# S32R372 register map
Vendor: Freescale Semiconductor, Inc.; Series: Qorivva; File version: 1.6
Registers are 32-bit, read-write, reset 0x0 unless marked. A register's access mark holds for its fields unless they carry their own. Offsets are from the block's base; [hi:lo] are bit positions; {n}, {i} and the like mark numbered series.

## CRC_1 — CRC
Base 0xFBF64000; register names take the prefix CRC_1_
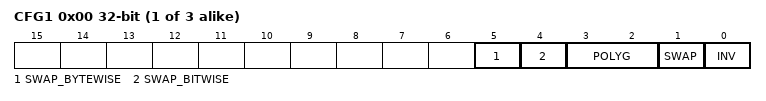
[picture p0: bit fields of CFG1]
0x00 CFG{i} (i=1..3; step 0x10) — Configuration Register
  [5] SWAP_BYTEWISE — Swap CRC_INP byte-wise
    0=Do not swap; 1=Perform byte-wise swap on CRC_INP input data internally for CRC-32 polynomial calculations
  [4] SWAP_BITWISE — Swap CRC_INP bit-wise
    0=Do not swap; 1=Perform bit-wise swap on CRC_INP input data internally for CRC-8 and CRC-16 polynomial calculations
  [3:2] POLYG — Polynomial selection
    0=CRC-CCITT polynomial; 1=CRC-32 polynomial; 2=CRC-8 polynomial; 3=CRC-8-H2F Autosar polynomial
  [1] SWAP — Swap selection
    0=No swap selection applied on the CRC_OUTP content; 1=Swap selection (MSB to LSB, LSB to MSB) applied on the CRC_OUTP content; in case of CRC-CCITT polynomial, the swap operation is applied on the 16 least-significant bits
  [0] INV — Inversion selection
    0=No inversion selection applied on the CRC_OUTP content; 1=Inversion selection (bit x bit) applied on the CRC_OUTP content
0x04 INP{i} (i=1..3; step 0x10) — Input Register
  [31:0] INP — Input data for the CRC computation
0x08 CSTAT{i} (i=1..3; step 0x10) reset 0xFFFFFFFF — Current Status Register
  [31:0] CSTAT — CRC signature status
0x0C OUTP{i} (i=1..3; step 0x10) ro reset 0xFFFFFFFF — Output Register
  [31:0] OUTP — Final CRC signature

## CRC_0 — CRC
Base 0xFFF64000; register names take the prefix CRC_0_
Registers as CRC_1.

## DMAMUX_1 — DMA channel multiplexor
Base 0xFBF6C000; register names take the prefix DMAMUX_1_
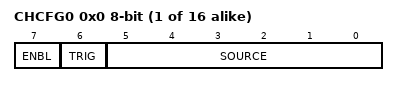
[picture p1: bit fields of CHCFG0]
{0x0+i} CHCFG{i} (i=0..15) 8-bit — Channel Configuration register
  [7] ENBL — DMA Channel Enable
    0=DMA channel is disabled. This mode is primarily used during configuration of the DMAMux. The DMA has separate channel enables/disables, which should be used to disable or reconfigure a DMA channel.; 1=DMA channel is enabled
  [6] TRIG — DMA Channel Trigger Enable
    0=Triggering is disabled. If triggering is disabled and ENBL is set, the DMA Channel will simply route the specified source to the DMA channel. (Normal mode); 1=Triggering is enabled. If triggering is enabled and ENBL is set, the DMAMUX is in Periodic Trigger mode.
  [5:0] SOURCE — DMA Channel Source (Slot)

## DMAMUX_0 — DMA channel multiplexor
Base 0xFFF6C000; register names take the prefix DMAMUX_0_
Registers as DMAMUX_1.

## CMU_0 — CMU
Base 0xFBFB0200; register names take the prefix CMU_0_
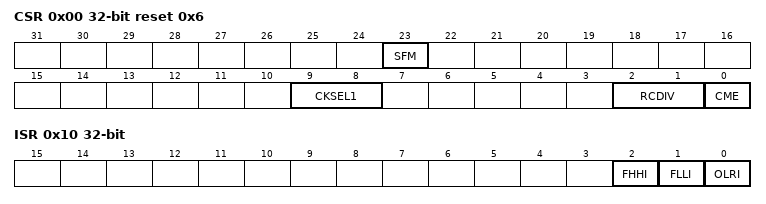
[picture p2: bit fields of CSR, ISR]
0x00 CSR reset 0x6 — CMU Control Status Register
  [23] SFM — Start frequency measure.
    0=Frequency measurement is completed or not yet started; 1=Frequency measurement is not completed
  [9:8] CKSEL1 — Frequency measure clock selection bit.
    0=CLKMT0_RMN is selected; 3=CLKMT0_RMN is selected
  [2:1] RCDIV — CLKMT0_RMN division factor.
    0=CLKMT0_RMN * 1 (No division); 1=CLKMT0_RMN * 2; 2=CLKMT0_RMN * 4; 3=CLKMT0_RMN * 8
  [0] CME — CLKMN1 monitor enable.
    0=CLKMN1 monitor is disabled; 1=CLKMN1 monitor is enabled
0x04 FDR ro — CMU Frequency Display Register
  [19:0] FD — Measured frequency bits.
0x08 HFREFR reset 0xFFF — CMU High Frequency Reference Register CLKMN1
  [11:0] HFREF — High Frequency reference value.
0x0C LFREFR — CMU Low Frequency Reference Register CLKMN1
  [11:0] LFREF — Low Frequency reference value.
0x10 ISR — CMU Interrupt Status Register
  [2] FHHI — CLKMN1 frequency higher than high reference event status.
    0=No FHH event; 1=FHH event occurred
  [1] FLLI — CLKMN1 frequency less than low reference event status.
    0=No FLL event; 1=FLL event occurred
  [0] OLRI — Oscillator frequency less than fCLKMT0_RMN * 2CMU_CSR[RCDIV]event status.
    0=No OLR event; 1=OLR event occurred
0x18 MDR — CMU Measurement Duration Register
  [19:0] MD — Measurement duration bits

## CMU_2 — CMU
Base 0xFBFB0280; register names take the prefix CMU_2_
Registers as CMU_0.

## CMU_3 — CMU
Base 0xFBFB02C0; register names take the prefix CMU_3_
Registers as CMU_0.

## CMU_4 — CMU
Base 0xFBFB0300; register names take the prefix CMU_4_
Registers as CMU_0.

## CMU_6 — CMU
Base 0xFBFB0380; register names take the prefix CMU_6_
Registers as CMU_0.

## CMU_7 — CMU
Base 0xFBFB03C0; register names take the prefix CMU_7_
Registers as CMU_0.

## CMU_8 — CMU
Base 0xFBFB0400; register names take the prefix CMU_8_
Registers as CMU_0.

## CMU_9 — CMU
Base 0xFBFB0440; register names take the prefix CMU_9_
Registers as CMU_0.

## CMU_10 — CMU
Base 0xFBFB0480; register names take the prefix CMU_10_
Registers as CMU_0.

## CMU_11 — CMU
Base 0xFBFB04C0; register names take the prefix CMU_11_
Registers as CMU_0.

## CMU_12 — CMU
Base 0xFBFB0500; register names take the prefix CMU_12_
Registers as CMU_0.
